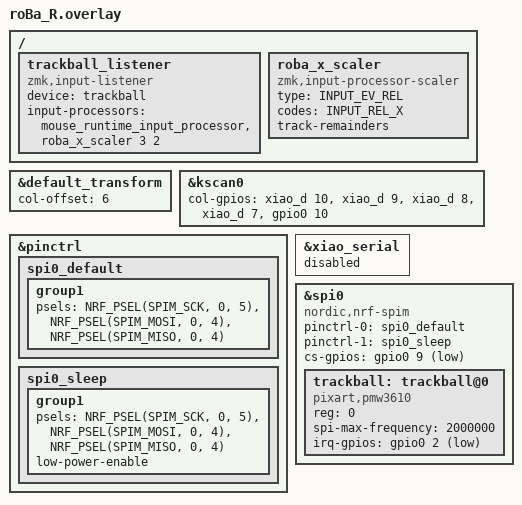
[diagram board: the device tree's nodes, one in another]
#include "roBa.dtsi"

&default_transform {
    col-offset = <6>;
};

&kscan0 {
        col-gpios
            = <&xiao_d 10 GPIO_ACTIVE_HIGH>
            , <&xiao_d 9 GPIO_ACTIVE_HIGH>
            , <&xiao_d 8 GPIO_ACTIVE_HIGH>
            , <&xiao_d 7 GPIO_ACTIVE_HIGH>
            , <&gpio0 10 GPIO_ACTIVE_HIGH>
            ;
};

/ {
    trackball_listener {
        status = "okay";
        compatible = "zmk,input-listener";
        device = <&trackball>;
    };
};

&pinctrl {
    spi0_default: spi0_default {
        group1 {
            psels = <NRF_PSEL(SPIM_SCK, 0, 5)>,
                <NRF_PSEL(SPIM_MOSI, 0, 4)>,
                <NRF_PSEL(SPIM_MISO, 0, 4)>;
        };
    };

    spi0_sleep: spi0_sleep {
        group1 {
            psels = <NRF_PSEL(SPIM_SCK, 0, 5)>,
                <NRF_PSEL(SPIM_MOSI, 0, 4)>,
                <NRF_PSEL(SPIM_MISO, 0, 4)>;
            low-power-enable;
        };
    };
};

&xiao_serial { status = "disabled"; };

&spi0 {
    status = "okay";
    compatible = "nordic,nrf-spim";
    pinctrl-0 = <&spi0_default>;
    pinctrl-1 = <&spi0_sleep>;
    pinctrl-names = "default", "sleep";
    cs-gpios = <&gpio0 9 GPIO_ACTIVE_LOW>;

    trackball: trackball@0 {
        status = "okay";
        compatible = "pixart,pmw3610";
        reg = <0>;
        spi-max-frequency = <2000000>;
        irq-gpios = <&gpio0 2 (GPIO_ACTIVE_LOW | GPIO_PULL_UP)>;
    };
};

/* ① 1.5倍にするプロセッサの定義をルートノードに追加 */
/ {
    roba_x_scaler: roba_x_scaler {
        compatible = "zmk,input-processor-scaler";
        #input-processor-cells = <2>;
        type = <INPUT_EV_REL>;
        codes = <INPUT_REL_X>;        /* X軸（横方向）のみを対象 */
        track-remainders;
    };
};

/* ② 既存の trackball_listener を上書き、または定義 */
/ {
    trackball_listener {
        compatible = "zmk,input-listener";
        device = <&trackball>;
        
        /* 既存の設定（あればそのまま残す）に、横1.5倍処理を「後ろ」に追加 */
        input-processors = 
            <&mouse_runtime_input_processor>, /* 元から記述があれば残す */
            <&roba_x_scaler 3 2>;             /* ★横方向を3/2倍（1.5倍）にする */
    };
};
